# psoc4000t register map
Vendor: Cypress Semiconductor; Series: PSoC4000T; File version: 1.0
CPU: CM0PLUS r0p1, little endian, no MPU, no FPU, VTOR, 2 interrupt priority bits
Registers are 32-bit, read-write, reset 0x0 unless marked. A register's access mark holds for its fields unless they carry their own. Offsets are from the block's base; [hi:lo] are bit positions; lines under a group give offsets from that group; {n}, {i} and the like mark numbered series; <NAME> marks a mode.

## MSCLP0 (part 1 of 3) — Low Power MultiSense Converter
Base 0x40290000
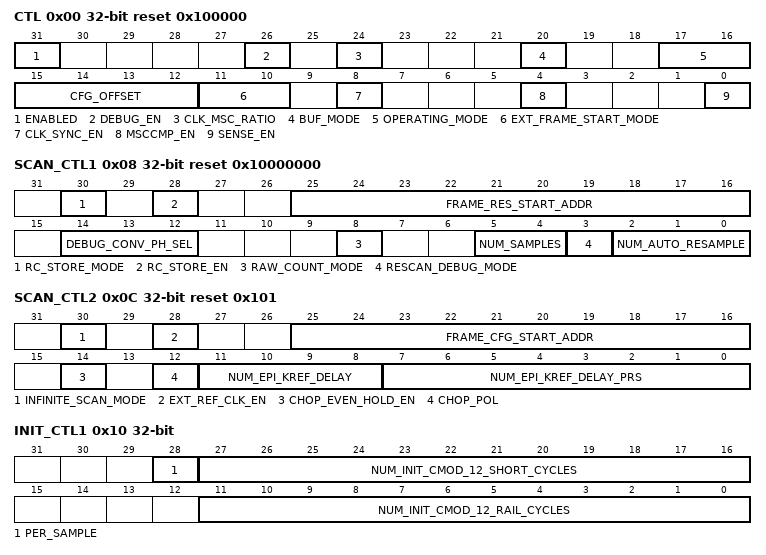
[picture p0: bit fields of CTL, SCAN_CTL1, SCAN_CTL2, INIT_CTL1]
0x00 CTL reset 0x100000 — Configuration and Control
  [31] ENABLED — Master enable of the MSCv3LP IP. Must be set to '1' for any operation to function. When '0' all analog components are off and all switches are open.
    0=DISABLED (N/A); 1=ENABLED (N/A)
  [26] DEBUG_EN — Master debug control for debug features. '0': Gate the logic for the following features: a) Debug conversion counter. b) Positive phase raw counter. c) Observability bus. '1': Enable all debug features
    0=DISABLED (N/A); 1=ENABLED (N/A)
  [24] CLK_MSC_RATIO — Control bit for logic that creates clk_msc from clk_hf (applicable if LP_AOS_PRESENT = 0). '0': Divided. clk_hf :: clk_msc is at least 2:1 divide ratio. Ratio controlled by clock_msc_pos_en and clock_msc_neg_en provided by PERI. '1': Pass-through. clk_hf :: clk_msc is 1:1.
    0=DIVIDED (N/A); 1=PASSTHROUGH (N/A)
  [20] BUF_MODE — Shield buffer operating mode select. '0': High bandwidth mode. '1': Shield mode.
    0=HIGH_BW_MODE (N/A); 1=SHIELD_MODE (N/A)
  [17:16] OPERATING_MODE — Sequencer FSM Operating Mode '0': CPU Mode. '1': Chained-Scan DMA Mode. '2': Autonomous Scan Multi Sensor Mode. '3': Low Power Always-On-Sense Mode.
    0=CPU (Frame scan configurations are stored in system RAM. Start of frame initiated by CPU via AHB (typically using FRAME_CMD.START_FRAME) or an external frame start. After each scan in frame, the end of scan interrupt is raised. The CPU extracts results and programs and starts the next scan. End of frame interrupt is produced so CPU can extract and process data. Firmware Rule: Intended to only be usable in the ACTIVE power domain only. Only usable in DEEP_SLEEP for a single scan frame since only INTR_LP.FRAME is asserted in DEEP_SLEEP (the INTR.SCAN interrupt is not available in DEEP_SLEEP).); 1=CS_DMA (Frame scan configurations are stored in system RAM. Start of frame is initiated by CPU via AHB (typically using FRAME_CMD.START_FRAME) or an external frame start. MSCv3LP requests DMA to write each scan configuration and read each scan result. All of the scans in the frame are chained via trigger to DMA. End of frame interrupt is produced so CPU can process data that the DMA has extracted. Firmware Rule: This mode is not usable if design time parameter CSDMA_MODE_PRESENT = 0. This mode is only usable when CSDMA_MODE_PRESENT = 1 in the ACTIVE power state since the external DMA controller is not available in DEEP_SLEEP.); 2=AS_MS (Frame scan configurations are stored in IP RAM. Start of frame initiated by CPU via AHB (expected to be FRAME_CMD.START_FRAME) or an external frame start. All of the scans in the frame are chained autonomously by Sequencer FSM. End of frame interrupt is produced so CPU can extract and process data. Firmware Rule: This mode is available in both ACTIVE and DEEP_SLEEP. In DEEP_SLEEP, the INTR_LP.FRAME interrupt will wake the system back to ACTIVE at the end of every frame.); 3=LP_AOS (Frame scan configurations are stored in IP RAM. Start of frame initiated by CPU via AHB (expected to be WAKEUP_CMD.START_FRAME_AOS) or an external frame start, and first frame starts after LP-AoS timer expire (as defined by WAKEUP_TIMER). Each scan in frame is chained autonomously by Sequencer FSM. Subsequent frames are initiated by LP-AoS timer expire. MRSS resources are power cycled where possible between frames. Wake up interrupt fired upon valid signal detection or frame timeout (LP-AoS FSM). Firmware Rule: This mode is available in both ACTIVE and DEEP_SLEEP. In DEEP_SLEEP, the rate of interrupts depends which causes in INTR_LP are enabled as wakeup sources. In general multiple frames (with periodic hardware controlled frame starts) may be executed before an interrupt is raised.)
  [15:12] CFG_OFFSET — Starting offset into SNS_* registers for each sensor configuration structure in local IP storage SENSOR_DATA. Defines the size of each configuration structure in SENSOR_DATA and the group of registers that change autonomously from sensor to sensor when scanning in AS_MS or LP_AOS modes. This setting is used by LOAD_CONFIG state in Sequencer FSM when reading from local memory and programming IP registers - the logic will load from the memory from this starting offset and store into the SNS_* registers up to and including SNS_CTL. For example, setting this value to 0xb means that each configuration structure starts from SNS_SCAN_CTL (and also includes SNS_CDAC_CTL and SNS_CTL). Firmware Rule: If using AS-MS/LP-AoS mode and engaging the Channel Engine (CE_CTL.ENABLED = 1), then CFG_OFFSET must be set to 0x0 since the Channel Engine related registers are offset from here (SNS_LP_AOS_SENSOR_CTL0). Note that if the design time parameter SENSE_PAD_NR <= 32, then SNS_SW_SEL_CSW_HI_MASK0,1 and 2 are skipped but offsets from SNS_SW_SEL_CSW_LO_MASK2 onwards assume they are there (i.e. CFG_OFFSET is set to 0x8 if the desired starting offset is SNS_SW_SEL_CSW_LO_MASK2).
  [11:10] EXT_FRAME_START_MODE — Control bit to enable external frame start of Sequencer FSM or LP-AoS Sequencer via GPIO. '0': External frame start capability off. External frame start affects neither Sequencer FSM or LP-AoS Sequencer FSM. Sequencer FSM is only sensitive to START_FRAME bit (or trigger from LP-AoS sequencer). LP-AoS Sequencer FSM is only sensitive to START_FRAME_AOS bit. '1': External frame start capability on for Sequencer FSM (usable for SCAN frames where firmware is responsible for enabling MRSS and not LP-AoS Sequencer). FSM sensitive to external frame start (and not sensitive to START_FRAME). This external start can be a new or pending external frame start event. '2': External frame start capability on for LP-AoS Sequencer FSM (usable for LP-SCAN/SD-SCAN frames where LP-AoS Sequencer is responsible for enabling MRSS). FSM sensitive to external frame start (and not sensitive to START_FRAME). This external start can be a new or pending external frame start event.
    0=DISABLED (N/A); 1=EXT_FRAME_SCAN (N/A); 2=EXT_FRAME_LP_SCAN (N/A)
  [8] CLK_SYNC_EN — Control bit to create external channel sync clock. Used for multi-chip operation. '0': msc_ext_sync_clk_out (and _out_en) tied 0. '1': Generate msc_ext_sync_clk_out using CLOCK_SYNC_DIV from the MRSS IMO and set msc_ext_sync_clk_out_en = 1.
    0=DISABLED (N/A); 1=ENABLED (N/A)
  [4] MSCCMP_EN — MSC Comparator Enable.
    0=DISABLED (N/A); 1=ENABLED (N/A)
  [0] SENSE_EN — Enables the sense modulator output. '0': All switches, static or dynamic, are open. '1': Switches can be closed/open as per MMIO setting and Sequencer FSM.
    0=DISABLED (N/A); 1=ENABLED (N/A)
0x04 SPARE — Spare MMIO
  [5:0] SPARE — Spare MMIO (Hard IP).
0x08 SCAN_CTL1 reset 0x10000000 — Scan Control 1
  [30] RC_STORE_MODE — Controls the behaviour of the result FIFO when it is full. 0: When full, ignore any subsequent writes. Any subsequent writes from hardware after the FIFO is full will cause a FIFO_OVERFLOW interrupt. 1: When full, any subsequent writes will restart from FRAME_RES_START_ADDR and overwrite existing data. The FIFO_OVERFLOW interrupt will not assert.
    0=STOP_ON_FULL (N/A); 1=WRAP (N/A)
  [28] RC_STORE_EN — Control whether raw counts are stored into result FIFO while scanning. Typically enabled, but may be disabled in a signal detection scenario where absolute raw counts are not required and are not stored to save power.
    0=DISABLED (N/A); 1=ENABLED (N/A)
  [25:16] FRAME_RES_START_ADDR — Base address (in terms of 32-bit SRAM entries) in SENSOR_DATA where the result FIFO exists. The size of the FIFO is from this location to the final location in SENSOR_DATA. Access to the result FIFO is done via RESULT_FIFO_RD but may also be accessed directly via SENSOR_DATA.
  [14:12] DEBUG_CONV_PH_SEL — Debug counter conversion chop phase select for DEBUG_CONV_COUNT. Must be between 0 and NUM_CONV. The number of conversions (or chop phases) for a given scan is controlled by NUM_CONV. Although only discrete values are possible for NUM_CONV, any conversion index up to this number may be selected up to NUM_CONV. For example if NUM_CONV = 7 (number of conversions is 8), then DEBUG_CONG_PH_SEL can be any value between 0 and 7 to select the particular conversion that the count is required for.
  [8] RAW_COUNT_MODE — Control bit to handle behaviour when RAW_COUNT exceeds 0xFFFF. '0': Saturate. In this scenario, RAW_COUNT is clamped at 0xFFFF and RESULT_FIFO_RD.OVERFLOW is set. '1': Overflow. In this scenario, RAW_COUNT rolls over and RESULT_FIFO_RD.OVERFLOW is set. This mode allows more sensitive tuning if measuring baseline capacitance is a don't care (e.g. SAR use case).
    0=SATURATE (N/A); 1=OVERFLOW (N/A)
  [5:4] NUM_SAMPLES — Number of samples (minus 1) to be scanned. NUM_SAMPLES > 1 results in autonomous scan same sensor (AS-SS) behaviour. This implies for a frame of e.g. 3 sensors (s0,s1,s2) with NUM_SAMPLES = 1 (2 samples per sensor), the result fifo will have two samples a and b for each sensor as follows: (s0_a,s0_b,s1_a,s1_b,s2_a,s2_b). Firmware Rule: Usable setting for NUM_SAMPLES is limited depending on the size of the result FIFO. Size of this FIFO determined by FRAME_RES_START_ADDR programming. Note that AS-SS is intended as a debug mode. If the stop on signal detection (STOP_ON_SD) feature is enabled, the behaviour of NUM_SAMPLES > 0 undefined since the sense sequencer FSM is not sensitive to status indicators from the Channel Engine in AS-SS mode until the last sample is complete.
  [3] RESCAN_DEBUG_MODE — If this bit is set all results (good and bad) generated by NUM_AUTO_RESAMPLE are stored. Debug feature. Firmware Rule: Usable setting for NUM_AUTO_RESAMPLE is limited depending on the size of the result FIFO. Size of this FIFO determined by FRAME_RES_START_ADDR programming.
    0=DISABLED (N/A); 1=ENABLED (N/A)
  [2:0] NUM_AUTO_RESAMPLE — If Sequencer detects a bad conversion and NUM_AUTO_RESAMPLE != 0, it will not store the bad result. Instead, it will automatically re-sample using current configuration without firmware intervention. This process repeats until a good conversion is produced or until the programmed maximum. If bad samples are produces for each programmed re-sample attempt, the final bad sample is stored.
0x0C SCAN_CTL2 reset 0x101 — Scan Control 2
  [30] INFINITE_SCAN_MODE — DFT bit that has the effect of keeping the Sequencer FSM in SUB_CONV forever to allow test measurements. With this bit set, the FSM remains in SUB_CONV once entered. The sub conversion counter will keep decrementing to zero and wrapping around to the maximum value and continue decrementing. The only way to exit from this state is via a soft reset of the block via CTL.ENABLED. Firmware Rule: If used, must be followed up with a soft reset using CTL.ENABLED when measurements complete.
    0=DISABLED (N/A); 1=ENABLED (N/A)
  [28] EXT_REF_CLK_EN — Control whether the clock used for external Cref clocking is enabled (clk_extfb). Firmware Rule: Must be enabled if any sensor is programmed to use clk_extfb.
    0=DISABLED (N/A); 1=ENABLED (N/A)
  [25:16] FRAME_CFG_START_ADDR — Pointer (in terms of 32-bit SRAM entries) to first sensor configuration of a frame in SENSOR_DATA. Hardware increments a local pointer from this start point. In LP-AoS mode, hardware returns to this pointer after the frame is complete prior to starting the next frame (after a timeout if using LP-AoS mode).
  [14] CHOP_EVEN_HOLD_EN — Use this bit to hold the chop value at the end of every even chop phase of NUM_CONV.
    0=DISABLED (N/A); 1=ENABLED (N/A)
  [12] CHOP_POL — Polarity of first chop phase. Hardware updates chop control locally from this point (via inversion and following CHOP_EVEN_HOLD_EN programming also).
  [11:8] NUM_EPI_KREF_DELAY — The duration of EPILOGUE defined in relation to Kref when (LFSR_MODE != PRS). The value is interpreted as Kref/4 increments. Duration of EPILOGUE calculated as: T_PRO_WAIT = NUM_EPI_KREF_DELAY*CEIL[(Kref)/4] This allows a range of [1, 15] which translates to [0.25Kref, 3.75Kref]. Firmware Rule: Note that setting this register to 0 is an illegal configuration (required to help timing closure in Sequencer FSM). Recommended programming value is 2.
    1=MIN (N/A)
  [7:0] NUM_EPI_KREF_DELAY_PRS — The duration of EPILOGUE defined in relation to Kref when (LFSR_MODE = PRS). The value is interpreted as Kref/4 increments. Duration of EPILOGUE calculated as: T_PRO_WAIT = NUM_EPI_KREF_DELAY_PRS*CEIL[(Kref)/4] This allows a range of [1, 255] which translates to [0.25Kref, 63.75Kref]. Firmware Rule: Note that setting this register to 0 is an illegal configuration (required to help timing closure in Sequencer FSM). Recommended programming value is 96.
0x10 INIT_CTL1 — Initialisation Control 1
  [28] PER_SAMPLE — Decides if coarse initialisation is done per sample when NUM_SAMPLES > 0 (i.e. more than one sample per scan). Applies to CMOD_SEL selected Cmod.
    0=DISABLED (N/A); 1=ENABLED (N/A)
  [27:16] NUM_INIT_CMOD_12_SHORT_CYCLES — Duration of the coarse short phase (shorting Cmod1 and Cmod2 in full-wave mode). Programmed in terms of clk_mod cycles. Firmware Rule: Should be set to zero in the case of half-wave mode.
  [11:0] NUM_INIT_CMOD_12_RAIL_CYCLES — Duration of the coarse initialisation phase (e.g. connecting Cmod1 to vdda and Cmod2 to vssa in full-wave mode). Programmed in terms of clk_mod cycles.
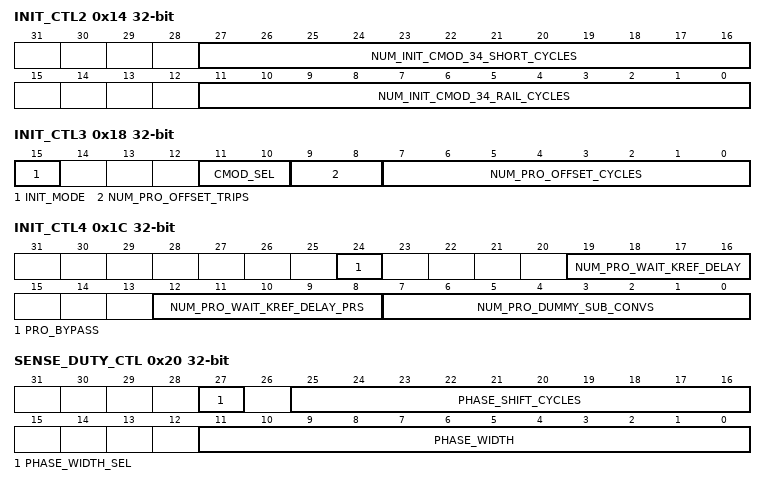
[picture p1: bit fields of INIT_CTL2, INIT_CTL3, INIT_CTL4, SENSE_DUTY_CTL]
0x14 INIT_CTL2 — Initialisation Control 2
  [27:16] NUM_INIT_CMOD_34_SHORT_CYCLES — Duration of the coarse short phase (shorting Cmod3 and Cmod4 in full-wave mode). Programmed in terms of clk_mod cycles. Firmware Rule: Should be set to zero in the case of half-wave mode.
  [11:0] NUM_INIT_CMOD_34_RAIL_CYCLES — Duration of the coarse initialisation phase (e.g. connecting Cmod3 to vdda and Cmod4 to vssa in full-wave mode). Programmed in terms of clk_mod cycles.
0x18 INIT_CTL3 — Initialisation Control 3
  [15] INIT_MODE — Determines autonomous initialisation behaviour during INIT_CMOD. Hardware Overriding: 0: Decode CMOD_SEL. CMOD_12: CMOD1 SW_PU = 1, CMOD2 SW_PD = 1 CMOD_34: CMOD3 SW_PU = 1, CMOD4 SW_PD = 1 CMOD_1: CMOD1 SW_PU = 1 CMOD_3: CMOD3 SW_PU = 1 1: Decode CMOD_SEL. Should be CMOD_1 or CMOD_3. CMOD_1: C1CA = 1, C1CC = 1, CMOD1 SW_AMUXB = 1, SOMB = 1, AYB_EN = CLOSED, AYB_CTL = CLOSED. CMOD_3: C3CA = 1, C3CC = 1, CMOD3 SW_AMUXB = 1, SOMB = 1, AYB_EN = CLOSED, AYB_CTL = CLOSED. Firmware Rule: Firmware should also close CBSO, FSP and one of BGRF/RMF/MBF to select type of reference.
    0=REFERENCE_VDDA (Used for full and half wave when Vdda is reference.); 1=REFERENCE_VREF (Used for half-wave when Vref is reference.)
  [11:10] CMOD_SEL — Select which Cmod are used and the cycle thresholds to be used for coarse initialisation. Note this field affects which Cmod switches are autonomously initialised by hardware as well as influencing the cycle counters as per INIT_MODE. 'CMOD_1' || 'CMOD_12': Use NUM_INIT_CMOD_12_RAIL_CYCLES and NUM_INIT_CMOD_12_SHORT_CYCLES 'CMOD_3' || 'CMOD_34': Use NUM_INIT_CMOD_34_RAIL_CYCLES and NUM_INIT_CMOD_34_SHORT_CYCLES Firmware Rule: Firmware must set a valid INIT_MODE with CMOD_SEL.
    0=CMOD_12 (Used for full-wave); 1=CMOD_34 (Used for full-wave); 2=CMOD_1 (Used for half-wave); 3=CMOD_3 (Used for half-wave)
  [9:8] NUM_PRO_OFFSET_TRIPS — Number of comparator trips required to be observed in PRO_OFFSET before proceeding to dummy cycles. Note that a 'trip' is defined as a change of state of the comparator (either a 0 to 1 or a 1 to 0 transition). A trip at the very start of PRO_OFFSET is considered a trip with respect to this count. Firmware Rule: If PRO_OFFSET is being used (either NUM_PRO_OFFSET_CYCLES != 0 or NUM_PRO_OFFSET_TRIPS != 0), SEL_CO_PRO_OFFSET must be > 0.
  [7:0] NUM_PRO_OFFSET_CYCLES — Maximum number of clk_mod cycles to be assigned for the PRO_OFFSET state. If NUM_PRO_OFFSET_TRIPS are observed before this timeout, exit at that point. Programming combinations: a) OFFSET_CYCLES == 0 && OFFSET_TRIPS == 0 -> Skip PRO_OFFSET b) OFFSET_CYCLES == 0 && OFFSET_TRIPS > 0 -> wait in PRO_OFFSET for OFFSET_TRIPS c) OFFSET_CYCLES > 0 && OFFSET_TRIPS == 0 -> wait in PRO_OFFSET for OFFSET_CYCLES d) OFFSET_CYCLES > 0 && OFFSET_TRIPS > 0 -> wait in PRO_OFFSET for the first of OFFSET_CYCLES and OFFSET_TRIPS. Note that if OFFSET_TRIPS > 0: i) SW_COTCA and SW_COCB autonomously adjust as per their description after each comparator trip apart from the last trip. Expect OFFSET_TRIPS-1 adjustments in PRO_OFFSET. ii) If FINE_MODE == COMPENSATION SW_CFTCA and SW_CFTCB autonomously adjust as per their description after each comparator trip apart from the last trip. Expect OFFSET_TRIPS-1 adjustments in PRO_OFFSET. iii) For both sets of switches above, after the last trip the switches revert to their programmed MMIO setting when exiting PRO_OFFSET. If OFFSET_TRIPS == 0 and OFFSET_CYCLES > 0: Intention is that PRO_OFFSET be a fixed duration. The autonomous behaviour for this case is the same as the OFFSET_TRIPS > 0 case, except that the number of trips (and hence the number of adjustments for (i) and (ii) above) are unknown in advance. At the end of OFFSET_CYCLES, the switches revert to their programmed MMIO setting when exiting PRO_OFFSET. Firmware Rule: If PRO_OFFSET is being used (either NUM_PRO_OFFSET_CYCLES != 0 or NUM_PRO_OFFSET_TRIPS != 0), SEL_CO_PRO_OFFSET must be > 0.
0x1C INIT_CTL4 — Initialisation Control 4
  [24] PRO_BYPASS — Decides whether to skip prologue (PRO_OFFSET/DUMMY/WAIT) for every conversion after the first chop phase (if any as defined by NUM_CONV).
    0=DISABLED (N/A); 1=ENABLED (N/A)
  [19:16] NUM_PRO_WAIT_KREF_DELAY — The duration of PRO_WAIT defined in relation to Kref when (LFSR_MODE != PRS). The value is interpreted as Kref/4 increments. Duration of PRO_WAIT calculated as: T_PRO_WAIT = NUM_PRO_WAIT_KREF_DELAY*CEIL[(Kref)/4] This allows a range of [0, 15] which translates to [0, 3.75Kref]. Firmware Rule: Recommended programming value is 2.
  [12:8] NUM_PRO_WAIT_KREF_DELAY_PRS — The duration of PRO_WAIT defined in relation to Kref when (LFSR_MODE = PRS). The value is interpreted as Kref/4 increments. Duration of PRO_WAIT calculated as: T_PRO_WAIT = NUM_PRO_WAIT_KREF_DELAY_PRS*CEIL[(Kref)/4] This allows a range of [0, 31] which translates to [0, 7.75Kref]. Firmware Rule: Recommended programming value is 16.
  [7:0] NUM_PRO_DUMMY_SUB_CONVS — Number of sub-conversions (dummy cycles) to be run during PRO_DUMMY.
0x20 SENSE_DUTY_CTL — Sense Clock Duty Cycle Control
  [27] PHASE_WIDTH_SEL — Select which phases the PHASE_WIDTH applies to: '0': PHASE_WIDTH corresponds to width of ph0 and ph2. '1': PHASE_WIDTH corresponds to width of ph1 and ph3.
    0=PH0_AND_PH2 (N/A); 1=PH1_AND_PH3 (N/A)
  [25:16] PHASE_SHIFT_CYCLES — Phase shift cycle control for ph0X and ph1X. Must be > 0 if PHASE_SHIFT_EN = 1.
  [11:0] PHASE_WIDTH — Control width (clk_mod cycles) of ph0 and ph2 OR ph1 and ph3. If set to zero, Fs is divided equally between all phases. This field is only applicable when LFSR_MODE = DIRECT_CLOCK.
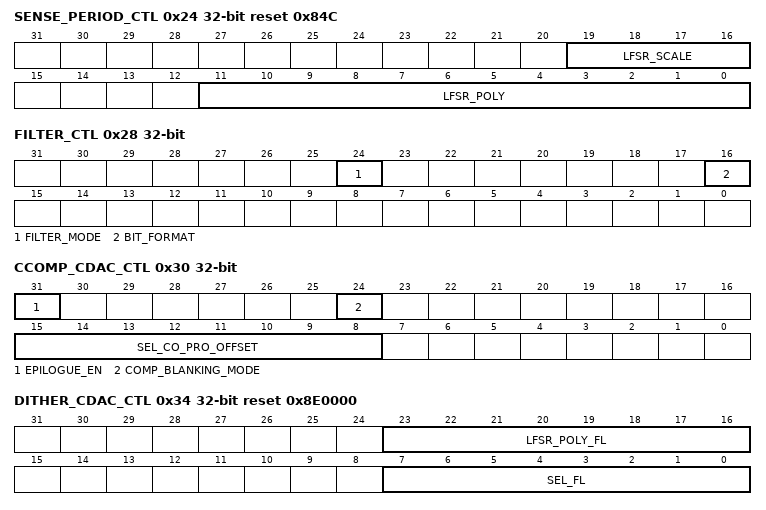
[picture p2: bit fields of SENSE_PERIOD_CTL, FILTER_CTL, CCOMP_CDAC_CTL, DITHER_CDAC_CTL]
0x24 SENSE_PERIOD_CTL reset 0x84C — Sense Clock Period Control
  [19:16] LFSR_SCALE — Shift the LFSR output left by LSFR_SCALE bits before adding to SENSE_DIV. This scaling is only applicable in spread spectrum mode. Firmware Rule: Note that the clock divider including the dithering term must fit in 12 bits, otherwise the result is undefined.
  [11:0] LFSR_POLY — Programmable polynomial to be used for the sense LFSR. For example (default): G(x) = X^12 + X^7 + X^4 + X^3 + 1 LFSR_POLY = 0x84C (1000_0100_1100). Note that LFSR_POLY[i] = 1 if X^(i+1) is included in the polynomial. The +1 feedback term is implied and doesn't need a programmable bit. Note if PLFSR_SENSE_PRESENT = 0, then polynomial is hardwired to 0x84C and not programmable.
0x28 FILTER_CTL — Filter Control
  [24] FILTER_MODE
    0=CIC1 (Use the standard first order counter low pass filter (equivalent to CIC1). Scan Time = 2^M Number of CIC1 sub-samples = 1 Time for first valid CIC1 sub-sample = 2^M Number of valid CIC1 sub-samples = 1 CIC1 Scan Resolution = 2^M = N); 1=CIC2 (Use CIC2 Filter. Advantage of CIC2 over CIC1 is a higher resolution result for an equivalent scan time. All valid sub-samples are averaged to achieve an overall sample result for the scan. Interrupt is fired for every valid sub-sample to facilitate debug of the individual sub-samples. Scan Time = 2^M Number of CIC2 sub-samples = (2^M)/N Time for first valid CIC2 sub-sample = 2N Number of valid CIC2 sub-samples = ((2^M)/N) - 1 CIC2 Scan Resolution = N^2)
  [16] BIT_FORMAT — Determines how the synchronised comparator output is interpreted by the filter pipeline. Firmware Rule: When FILTER_MODE = CIC1, BIT_FORMAT should be UNSIGNED. If CE_CTL.ENABLED = 1, then BIT_FORMAT should be UNSIGNED.
    0=UNSIGNED (Input values [0,+1]); 1=SIGNED (Input values [-1,+1]. In this scenario a value of 0 is interpreted as -1.)
0x30 CCOMP_CDAC_CTL — Compensation CAPDAC Control
  [31] EPILOGUE_EN — Control on whether Ccomp is active during EPILOGUE for final balancing in a conversion. Note that for this bit to enable Ccomp during EPILOGUE, need SEL_CO > 0 or FINE_MODE = COMPENSATION.
    0=DISABLED (N/A); 1=ENABLED (N/A)
  [24] COMP_BLANKING_MODE — Control on type of compensation blanking applied when compensation blanking is enabled (COMP_BLANKING_EN = 1). '0': Compensation is enabled for 25 percent of the 'sampling-balancing' window during each sub-conversion. Absolute percentage depends on LFSR_MODE. '1': Compensation is enabled for 50 percent of the 'sampling-balancing' window during each sub-conversion. Absolute percentage depends on LFSR_MODE. In 2-phase mode: Above applies from the start of both ph0 and ph1. In 4-phase mode: Above applies from the start of ph1 and ph3. Notes: * In 4-phase mode if COMP_BLANKING_EN = 1, there will be no compensation in very first ph0 of SUB_CONV - it will commence in first ph1. * In 4-phase mode (depending on setting) starting in ph3 could mean it stays on into the next ph0. * In EPILOGUE, COMP_BLANKING_EN = 1, compensation is fully off (so ignore EPILOGUE_EN even if EPILOGUE_EN = 1) in this case.
    0=COMP_EN_25 (N/A); 1=COMP_EN_50 (N/A)
  [15:8] SEL_CO_PRO_OFFSET — Select value for Compensation CAPDAC size during PRO_OFFSET until the first comparator trip is observed. After the first trip in PRO_OFFSET, the following overriding applies: if (SEL_CO_PRO_OFFSET < 8) a Compensation CAPDAC code of 1 applies for the rest of PRO_OFFSET. else SEL_CO_PRO_OFFSET/8 applies for the rest of PRO_OFFSET. On egress from PRO_OFFSET, SEL_CO applies. Hardware Overriding: Note that clk_comp runs at clk_mod during PRO_OFFSET. The CAPDAC code is overridden after the first observed trip in PRO_OFFSET as described above. Firmware Rule: If PRO_OFFSET is being used (either NUM_PRO_OFFSET_CYCLES != 0 or NUM_PRO_OFFSET_TRIPS != 0), SEL_CO_PRO_OFFSET must be > 0.
0x34 DITHER_CDAC_CTL reset 0x8E0000 — Flatspot/Dither CAPDAC Switch Control
  [23:16] LFSR_POLY_FL — Dither/Flatspot CAPDAC LFSR polynomial. Uses same encoding as the spread spectrum polynomial LFSR_POLY. For example (default): G(x) = X^8 + X^4 + X^3 + X^2 + 1 LFSR_POLY_FL = 0x8E (1000_1110). Note that LFSR_POLY_FL[i] = 1 if X^(i+1) is included in the polynomial. The +1 feedback term is implied and doesn't need a programmable bit. Note if PLFSR_FL_PRESENT = 0, then polynomial is hardwired to 0x8E and not programmable.
  [7:0] SEL_FL — Select value for Dither/Flatspot CAPDAC size. If dithering is enabled (FL_MODE = DITHER), this is the seed value for the LFSR. If FL_MODE = OFFSET, this value is presented directly to the hard IP as the CAPDAC code. If FL_MODE = OFF, this value is ignored and 0x00 is presented to the hard IP. Firmware Rule: If FL_MODE = DITHER, SEL_FL != 0 since it seeds the LFSR. Likely default seed is 0xFF. Hardware Overriding: See description of FL_MODE register.
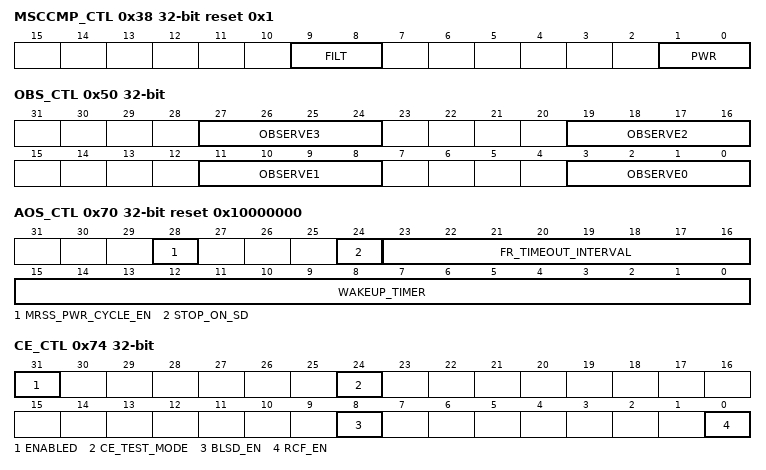
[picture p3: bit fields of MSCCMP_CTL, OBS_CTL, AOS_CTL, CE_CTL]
0x38 MSCCMP_CTL reset 0x1 — MSC Comparator Control
  [9:8] FILT — MSC comparator filter frequency select (corner frequencies - 90 percent settling). Firmware Guideline: Recommend 290MHz when clk_mod = 48MHz, 115/64 Mhz if clk_mod = 24MHz and 46MHz for any lower clk_mod frequency.
    0=FREQ_290MHZ (N/A); 1=FREQ_115MHZ (N/A); 2=FREQ_64MHZ (N/A); 3=FREQ_46MHZ (N/A)
  [1:0] PWR — Power control setting on MSC comparator to allow noise reduction at the cost of current consumption (less noise, more power).
    0=X_0P5 (N/A); 1=N/A; 2=X_1P5 (N/A); 3=X_2 (N/A)
0x50 OBS_CTL — Observability Control
  [27:24] OBSERVE3 — Selects the source for observe output signal 3: 0-14: See OBSERVE0. 15: Sequencer FSM state bit 3.
    0=FS (N/A); 1=COMP_OUT (N/A); 2=COMP_OUT_ADV (N/A); 3=COMP_OUT_SYNC (N/A); 4=COUNTER_LSB (N/A); 5=SCAN_DONE (N/A); {v}=PH{v-6} (N/A) (v=6..9); 10=PH0X (N/A); 11=PH1X (N/A); 12=COMP_CLK_ENABLED (N/A); 13=UNUSED_1 (N/A); 14=SM_STATE_4 (N/A); 15=SM_STATE_3 (N/A)
  [19:16] OBSERVE2 — Selects the source for observe output signal 2: 0-14: See OBSERVE0. 15: Sequencer FSM state bit 2.
    0=FS (N/A); 1=COMP_OUT (N/A); 2=COMP_OUT_ADV (N/A); 3=COMP_OUT_SYNC (N/A); 4=COUNTER_LSB (N/A); 5=SCAN_DONE (N/A); {v}=PH{v-6} (N/A) (v=6..9); 10=PH0X (N/A); 11=PH1X (N/A); 12=COMP_CLK_ENABLED (N/A); 13=UNUSED_1 (N/A); 14=SM_STATE_4 (N/A); 15=SM_STATE_2 (N/A)
  [11:8] OBSERVE1 — Selects the source for observe output signal 1: 0-14: See OBSERVE0. 15: Sequencer FSM state bit 1.
    0=FS (N/A); 1=COMP_OUT (N/A); 2=COMP_OUT_ADV (N/A); 3=COMP_OUT_SYNC (N/A); 4=COUNTER_LSB (N/A); 5=SCAN_DONE (N/A); {v}=PH{v-6} (N/A) (v=6..9); 10=PH0X (N/A); 11=PH1X (N/A); 12=COMP_CLK_ENABLED (N/A); 13=UNUSED_1 (N/A); 14=SM_STATE_4 (N/A); 15=SM_STATE_1 (N/A)
  [3:0] OBSERVE0 — Selects the source for observe output signal 0: 0: Fs 1: Comparator Output (direct from hard IP). 2: Comparator Output captured on clk_hf_adv. 3: Comparator Output captured on clk_mod. 4: Current raw counter LSB. 5: Scan Done (hardware set signal for INTR.SCAN) 6: ph0. 7: ph1. 8: ph2. 9: ph3. 10: ph0X 11: ph1X 12: Compensation clock enabled. Note: this can be programmed to be as short as 1x clk_msc in duration (not a typical usecase), so minimum pulse width specifications on the GPIO being used determine when COMP_CLK_ENABLED can be viewed. 13: Unused (0). 14: Sequencer FSM state bit 4. 15: Sequencer FSM state bit 0.
    0=FS (N/A); 1=COMP_OUT (N/A); 2=COMP_OUT_ADV (N/A); 3=COMP_OUT_SYNC (N/A); 4=COUNTER_LSB (N/A); 5=SCAN_DONE (N/A); {v}=PH{v-6} (N/A) (v=6..9); 10=PH0X (N/A); 11=PH1X (N/A); 12=COMP_CLK_ENABLED (N/A); 13=UNUSED_1 (N/A); 14=SM_STATE_4 (N/A); 15=SM_STATE_0 (N/A)
0x70 AOS_CTL reset 0x10000000 — Always On Scanning Control
  [28] MRSS_PWR_CYCLE_EN — Control bit to enable/disable hardware controlled power cycling of MRSS resources (reference, IMO, pump). This power cycling occurs at the end of frames initiated via FRAME_START_AOS that do not result in an interrupt. By default this is enabled to achieve maximum power savings. Note that independent of MRSS_PWR_CYCLE_EN, the MSCv3LP analog circuit is also disabled at the same time as the MRSS (even though CTL.ENABLED = 1). This autonomous disabling of the hard IP has the same effect as CTL.ENABLED = 0. Firmware Rule: Hardware power cycling must be disabled if firmware intends on accessing any MMIO in SNS_STRUCTLP during a time window when the AoS FSM is active. This is because the MMIO on SNS_STRUCTLP are clocked on the local IMO. If an access to this MMIO bank occurs while the IMO is power cycled, the transaction will be lost and the bridge cannot respond to this transaction.
    0=DISABLED (N/A); 1=ENABLED (N/A)
  [24] STOP_ON_SD — Stop on signal detection control bit. If set and a signal is detected mid frame, the frame will terminate immediately and assert the SIG_DET interrupt. Otherwise only SIG_DET asserts the frame continues to the end of the frame (at which point FR_TIMEOUT asserts regardless of the current frame index with respect to FR_TIMEOUT_INTERVAL).
    0=DISABLED (N/A); 1=ENABLED (N/A)
  [23:16] FR_TIMEOUT_INTERVAL — Threshold for the number of consecutive frames initiated by the LP-AoS FSM before asserting FR_TIMEOUT interrupt. Once this threshold is met, the LP-AoS FSM asserts the FR_TIMEOUT interrupt. Setting this register to 0 disables this feature. If signal detection is enabled and detected (via SIG_DET) on a frame index in between the timeout interval, FR_TIMEOUT asserts at the end of this frame. Absolute time between consecutive INTR_LP.FR_TIMEOUT (with no signal detection): FR_TIMEOUT_INTERVAL * ((WAKEUP_TIMER+1) * 1/32kHz)
  [15:0] WAKEUP_TIMER — Timer interval in terms of clk_lf cycles (minus 1) between AoS frames when using LP-AoS FSM. Assumes a 32kHz operating clock (clk_lf). Desired range is typically 1->2000ms. Intended usage is in DEEP_SLEEP where only the ILO is on and every interval as defined by WAKEUP_TIMER, the timer restarts in parallel to the MRSS waking up. Once awake with the local MRSS IMO enabled, a frame scan is initiated. If no wakeup condition is detected during this frame, the MRSS shuts down again and only the ILO logic serving the wakeup timer is operating until the next WAKEUP_TIMER expire and the above process repeats. Firmware Rule: WAKEUP_TIMER should be programmed to account for the expected worst case frame time. If WAKEUP_TIMER is programmed in such a way as the hardware counter that counts until it WAKEUP_TIMER reaches WAKEUP_TIMER before the current frame N completes, the frame N+1 cannot start until frame N is complete (so slower than the programmed frame rate). The hardware counter will saturate at 0xFFFF to prevent rollover of the counter in this scenario - this ensures that frame N+1 will start as soon as possible after frame N.
0x74 CE_CTL — Channel Engine Control
  [31] ENABLED — Channel Engine enable. If set = 1, then the Channel Engine processes the raw counts produced by the CIC1/CIC2 filter according to RCF_EN and BLSD_EN. Firmware Rule: If FILTER_CTL.BIT_FORMAT = SIGNED, the Channel Engine cannot be used (CE_CTL.ENABLED must be 0).
    0=DISABLED (N/A); 1=ENABLED (N/A)
  [24] CE_TEST_MODE — Channel Engine test mode control
    0=FUNCTIONAL_MODE (N/A); 1=TEST_MODE (N/A)
  [8] BLSD_EN — If set (and CE_CTL.ENABLED == 1), then the Channel Engine executes hardware baselining and signal detection.
    0=DISABLED (N/A); 1=ENABLED (N/A)
  [0] RCF_EN — If set (and CE_CTL.ENABLED == 1), then the Channel Engine executes the raw count filter IIR on the raw counts produced by the CIC1/CIC2 filter. Firmware Rule: Note that raw count filtering is not recommended if firmware back calculation is required for the CIC2 filter (see RESULT_FIFO_RD.RAW_COUNT description).
    0=DISABLED (N/A); 1=ENABLED (N/A)
0x80 PUMP_CTL — Local MRSS Pump Control
  [0] PUMP_MODE — Local pump mode control. The programming of this register is acted on by the LP-AoS FSM when controlling the pump settings prior to periodic scanning.
    0=BYPASSED (Bypass the local pump (used when vdda > 4V).); 1=USED (Use the local pump (used when vdda < 4V).)
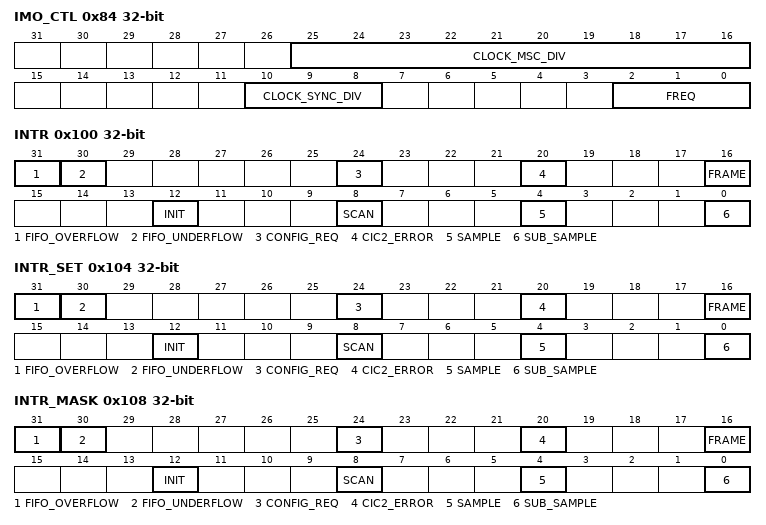
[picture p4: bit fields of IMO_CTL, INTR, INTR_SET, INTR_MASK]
0x84 IMO_CTL — Local MRSS IMO Control
  [25:16] CLOCK_MSC_DIV — Clock division ratio for clk_imo_msc to clk_msc. This specifies the frequency at which the main MSCv3LP digital is running at (clk_msc) and is equivalent to the modulator clock (clk_mod). Note that CLOCK_REF_RATE defines the relationship of clk_ref to clk_mod.
  [10:8] CLOCK_SYNC_DIV — Clock division for clk_imo_msc to clk_sync. This clock (clk_sync) is enabled via CLK_SYNC_EN for the master channel in a multi-chip topology. Firmware Rule: The frequency of clk_sync should be tuned to account for open drain rise time of GPIO used for consensus of multi chip ext_sync signals and any board delays between chips.
    {v}=DIV_BY_{v+1} (N/A) (v=0..7)
  [2:0] FREQ — Select operating frequency of MRSS clk_imo_msc
    0=24_MHZ (IMO runs at 24 MHz); 1=28_MHZ (IMO runs at 28 MHz); 2=32_MHZ (IMO runs at 32 MHz); 3=36_MHZ (IMO runs at 36 MHz); 4=40_MHZ (IMO runs at 40 MHz); 5=44_MHZ (IMO runs at 44 MHz); 6=48_MHZ (IMO runs at 48 MHz)
0x100 INTR — MSCv3 Interrupt Cause Register
  [31] FIFO_OVERFLOW — Result FIFO overflow condition.
  [30] FIFO_UNDERFLOW — Result FIFO underflow condition.
  [24] CONFIG_REQ — Request for scan configuration and scan start. The Sequencer FSM is entering WAIT_SCAN_START when this interrupt is raised. This interrupt can be used in CPU mode in a multi-channel scenario with external frame start to indicate to firmware that it is required to configure the channel and start a scan.
  [20] CIC2_ERROR — CIC2 error detected. This bit is set at the end of a sample if the number of valid CIC2 sub-samples is not one of [1,2,4,8,16,32,64,128,256]. At the end of a CIC2 sample, RESULT_FIFO_RD.RAW_COUNT contains the average of the valid sub-samples observed during that sample. The average is computed by a power of 2 shift as per below for the number of valid CIC2 samples observed: [0,1] -> no division (not a typical use case since an average of multiple sub-samples is desired) [2] -> divide by 2 [3,4] -> divide by 4 [5,8] -> divide by 8 [9,16] -> divide by 16 [17,32] -> divide by 32 [33,64] -> divide by 64 [65,128] -> divide by 128 129+ -> divide by 256 The RESULT_FIFO_RD.RAW_COUNT value is only the true average if the number of valid CIC2 sub-samples is {1,2,4,8,16,32,64,128,256}. However, in the other cases firmware can back-calculate the real average from the computed average (RAW_COUNT) and the divisor used to compute that average (1,2,4,8,16,32,54,128,256 above) as follows assuming the number of valid sub-samples is known: Real_Average = Computed_Average*(Computed_Divider/NumSubSamples) If the number of sub-samples exceeds 256, this cannot be reliably computed due to internal hardware overflows.
  [16] FRAME — A single frame is complete.
  [12] INIT — Coarse initialisation complete. For debug purposes.
  [8] SCAN — A single scan is complete.
  [4] SAMPLE — A single sample is complete. For debug purposes.
  [0] SUB_SAMPLE — A valid CIC2 sub-sample is complete. To facilitate firmware averaging of sub-samples. For debug purposes.
0x104 INTR_SET — MSCv3 Interrupt Set Register
  [31] FIFO_OVERFLOW — Write with '1' to set corresponding bit in interrupt request register (a write of '0' has no effect).
  [30] FIFO_UNDERFLOW — Write with '1' to set corresponding bit in interrupt request register (a write of '0' has no effect).
  [24] CONFIG_REQ — Write with '1' to set corresponding bit in interrupt request register (a write of '0' has no effect).
  [20] CIC2_ERROR — Write with '1' to set corresponding bit in interrupt request register (a write of '0' has no effect).
  [16] FRAME — Write with '1' to set corresponding bit in interrupt request register (a write of '0' has no effect).
  [12] INIT — Write with '1' to set corresponding bit in interrupt request register (a write of '0' has no effect).
  [8] SCAN — Write with '1' to set corresponding bit in interrupt request register (a write of '0' has no effect).
  [4] SAMPLE — Write with '1' to set corresponding bit in interrupt request register (a write of '0' has no effect).
  [0] SUB_SAMPLE — Write with '1' to set corresponding bit in interrupt request register (a write of '0' has no effect).
0x108 INTR_MASK — MSCv3 Interrupt Mask Register
  [31] FIFO_OVERFLOW — Mask bit for corresponding bit in interrupt cause register.
  [30] FIFO_UNDERFLOW — Mask bit for corresponding bit in interrupt cause register.
  [24] CONFIG_REQ — Mask bit for corresponding bit in interrupt cause register.
  [20] CIC2_ERROR — Mask bit for corresponding bit in interrupt cause register.
  [16] FRAME — Mask bit for corresponding bit in interrupt cause register.
  [12] INIT — Mask bit for corresponding bit in interrupt cause register.
  [8] SCAN — Mask bit for corresponding bit in interrupt cause register.
  [4] SAMPLE — Mask bit for corresponding bit in interrupt cause register.
  [0] SUB_SAMPLE — Mask bit for corresponding bit in interrupt cause register.
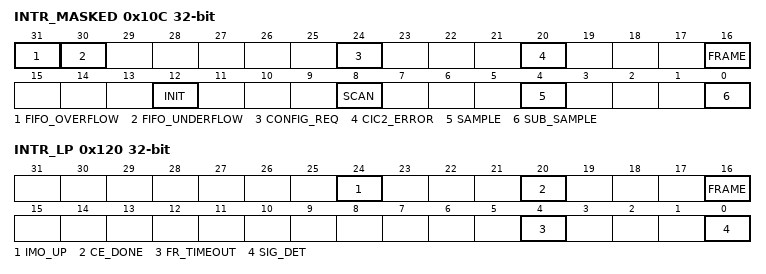
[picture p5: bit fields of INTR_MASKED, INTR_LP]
0x10C INTR_MASKED ro — MSCv3 Interrupt Masked Register
  [31] FIFO_OVERFLOW — Logical AND of corresponding INTR and INTR_MASK bits.
  [30] FIFO_UNDERFLOW — Logical AND of corresponding INTR and INTR_MASK bits.
  [24] CONFIG_REQ — Logical AND of corresponding INTR and INTR_MASK bits.
  [20] CIC2_ERROR — Logical AND of corresponding INTR and INTR_MASK bits.
  [16] FRAME — Logical AND of corresponding INTR and INTR_MASK bits.
  [12] INIT — Logical AND of corresponding INTR and INTR_MASK bits.
  [8] SCAN — Logical AND of corresponding INTR and INTR_MASK bits.
  [4] SAMPLE — Logical AND of corresponding INTR and INTR_MASK bits.
  [0] SUB_SAMPLE — Logical AND of corresponding INTR and INTR_MASK bits.
0x120 INTR_LP — Low Power Interrupt Cause Register
  [24] IMO_UP — MSCv3LP logic has turned on the MRSS IMO. Firmware Rule: CTL.ENABLED = 0 does not reset the cause for this interrupt. This is because CTL.ENABLED must be 0 when booting up the MRSS via firmware. Once IMO_UP is detected, CTL.ENABLED can be set to 1 to release reset to tbe block synchronously to the newly started MRSS IMO.
  [20] CE_DONE — Channel Engine done signal. Asserted '1' at the end of the Channel Engine processing pipeline. For use in debug firmware in CE_TEST_MODE after initiating CE_START. Not intended to be used as a DEEP_SLEEP wakeup source.
  [16] FRAME — A single frame is complete. Identical to INTR.FRAME except a DEEP_SLEEP wakeup variant.
  [4] FR_TIMEOUT — LP-AoS has detected a frame timeout.
  [0] SIG_DET — LP-AoS has detected a signal wakeup.
